AUTOSAR XML (schema 00050)
package /FCASWCs
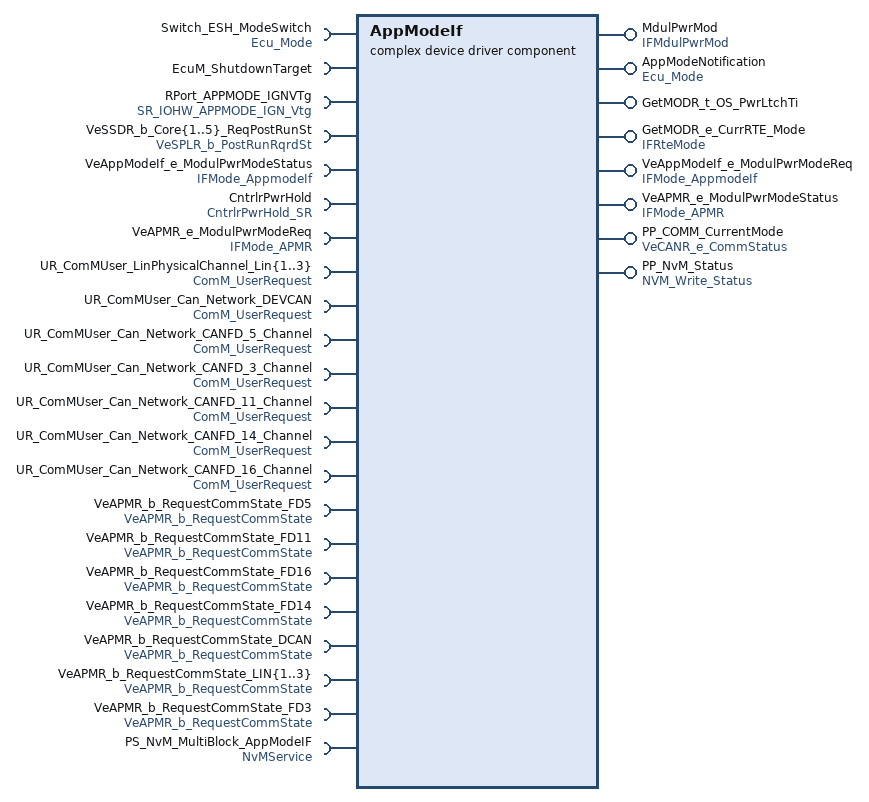
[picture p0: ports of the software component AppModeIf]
  complex device driver sw component type AppModeIf  # App Interface
    provide port MdulPwrMod: provided-interface=IFMdulPwrMod
    require port Switch_ESH_ModeSwitch: required-interface=Ecu_Mode
    provide port AppModeNotification: provided-interface=Ecu_Mode
    require port EcuM_ShutdownTarget: required-interface=EcuM_ShutdownTarget
    provide port GetMODR_t_OS_PwrLtchTi: provided-interface=GetMODR_t_OS_PwrLtchTi
    provide port GetMODR_e_CurrRTE_Mode: provided-interface=IFRteMode
      provided-com-specs:
        operation=GetMODR_e_CurrRTE_Mode, queue-length=1
        operation=GetMODR_b_InStrtUpMode, queue-length=1
        operation=GetMODR_b_InRunMode, queue-length=1
        operation=GetMODR_b_InPostRunMode, queue-length=1
        operation=GetMODR_b_InShtDwnMode, queue-length=1
        operation=GetMODR_b_InWakeUpMode, queue-length=1
    6 x require port:
      RPort_APPMODE_IGNVTg: required-interface=SR_IOHW_APPMODE_IGN_Vtg
      VeSSDR_b_Core{1..5}_ReqPostRunSt: required-interface=VeSPLR_b_PostRunRqrdSt
    provide port VeAppModeIf_e_ModulPwrModeReq: provided-interface=IFMode_AppmodeIf
    require port VeAppModeIf_e_ModulPwrModeStatus: required-interface=IFMode_AppmodeIf
    require port CntrlrPwrHold: required-interface=CntrlrPwrHold_SR
    provide port VeAPMR_e_ModulPwrModeStatus: provided-interface=IFMode_APMR
    4 x require port:
      VeAPMR_e_ModulPwrModeReq: required-interface=IFMode_APMR
      UR_ComMUser_LinPhysicalChannel_Lin{1..3}: required-interface=ComM_UserRequest
    provide port PP_COMM_CurrentMode: provided-interface=VeCANR_e_CommStatus
    16 x require port:
      UR_ComMUser_Can_Network_DEVCAN: required-interface=ComM_UserRequest
      UR_ComMUser_Can_Network_CANFD_5_Channel: required-interface=ComM_UserRequest
      UR_ComMUser_Can_Network_CANFD_3_Channel: required-interface=ComM_UserRequest
      UR_ComMUser_Can_Network_CANFD_11_Channel: required-interface=ComM_UserRequest
      UR_ComMUser_Can_Network_CANFD_14_Channel: required-interface=ComM_UserRequest
      UR_ComMUser_Can_Network_CANFD_16_Channel: required-interface=ComM_UserRequest
      VeAPMR_b_RequestCommState_FD5: required-interface=VeAPMR_b_RequestCommState
      VeAPMR_b_RequestCommState_FD11: required-interface=VeAPMR_b_RequestCommState
      VeAPMR_b_RequestCommState_FD16: required-interface=VeAPMR_b_RequestCommState
      VeAPMR_b_RequestCommState_FD14: required-interface=VeAPMR_b_RequestCommState
      VeAPMR_b_RequestCommState_DCAN: required-interface=VeAPMR_b_RequestCommState
      VeAPMR_b_RequestCommState_LIN{1..3}: required-interface=VeAPMR_b_RequestCommState
      VeAPMR_b_RequestCommState_FD3: required-interface=VeAPMR_b_RequestCommState
      PS_NvM_MultiBlock_AppModeIF: required-interface=NvMService
    provide port PP_NvM_Status: provided-interface=NVM_Write_Status
    behavior IBAppModeIf: data-type-mapping=[BswMMappingSet, MG_Shutdown_Mapping, SR_IO_HW_APPMODEIF_MappingSet, ADTtoIDTMapping], handle-termination-and-restart=NO-SUPPORT
      init event InitEvent: start-on-event=InitMode
      5 x operation invoked event:
        IsInPostRunMode: start-on-event=GetMODR_b_InPostRunMode, operation=GetMODR_e_CurrRTE_Mode.GetMODR_b_InPostRunMode
        IsInRunMode: start-on-event=GetMODR_b_InRunMode, operation=GetMODR_e_CurrRTE_Mode.GetMODR_b_InRunMode
        IsInShutDownMode: start-on-event=GetMODR_b_InShtDwnMode, operation=GetMODR_e_CurrRTE_Mode.GetMODR_b_InShtDwnMode
        IsInStartUpMode: start-on-event=GetMODR_b_InStrtUpMode, operation=GetMODR_e_CurrRTE_Mode.GetMODR_b_InStrtUpMode
        IsInWakeUpMode: start-on-event=GetMODR_b_InWakeUpMode, operation=GetMODR_e_CurrRTE_Mode.GetMODR_b_InWakeUpMode
      5 x timing event, all with period=0.01:
        TimingEvent: start-on-event=AppModeMgr
        TE_Mode: start-on-event=RE_Mode
        TE_APMR_Mode: start-on-event=RE_APMR_Mode
        TE_Comm_Status: start-on-event=RE_Comm_Status
        TE_NvMJobEndNotification: start-on-event=RE_NvMJobEndNotification
      port-api-options:
        enable-take-address=false, indirect-api=false, port=GetMODR_e_CurrRTE_Mode
        enable-take-address=false, indirect-api=false, port=MdulPwrMod
        enable-take-address=false, indirect-api=false, port=Switch_ESH_ModeSwitch
      15 x runnable:
        AppModeMgr: symbol=AppModeIf_AppModeMgr
          data-receive-point-by-values:
            6 x access:
              DRPV_IOHW_APPMODE_IGNVtg_VDP_0: accessed-variable=RPort_APPMODE_IGNVTg.IOHW_APPMODE_IGNVtg_VDP
              DRPV_VeSPLR_b_PostRunRqrdSt_0: accessed-variable=VeSSDR_b_Core1_ReqPostRunSt.VeSPLR_b_PostRunRqrdSt
              DRPV_VeSPLR_b_PostRunRqrdSt_1: accessed-variable=VeSSDR_b_Core2_ReqPostRunSt.VeSPLR_b_PostRunRqrdSt
              DRPV_VeSPLR_b_PostRunRqrdSt_2: accessed-variable=VeSSDR_b_Core3_ReqPostRunSt.VeSPLR_b_PostRunRqrdSt
              DRPV_VeSPLR_b_PostRunRqrdSt_3: accessed-variable=VeSSDR_b_Core4_ReqPostRunSt.VeSPLR_b_PostRunRqrdSt
              DRPV_VeSPLR_b_PostRunRqrdSt_4: accessed-variable=VeSSDR_b_Core5_ReqPostRunSt.VeSPLR_b_PostRunRqrdSt
          mode-access-point mode-group=MdulPwrMod.AppMode_MDGP_ESH_Mode:
            ident MAP_AppModeSwitch_ModeGroup
          mode-access-point mode-group=AppModeNotification.BswMEcuModeDclGroups:
            ident MAP_AppModeNotification_BswMEcuModeDclGroups
          mode-access-point mode-group=Switch_ESH_ModeSwitch.BswMEcuModeDclGroups:
            ident MAP_Switch_ESH_ModeSwitch_BswMEcuModeDclGroups
          mode switch point MSP_AppModeSwitch_ModeGroup: mode-group=MdulPwrMod.AppMode_MDGP_ESH_Mode
          mode switch point MSP_AppModeNotification_BswMEcuModeDclGroups: mode-group=AppModeNotification.BswMEcuModeDclGroups
          parameter access SCPVA_KeMODR_t_OS_PwrDwnMaxTi
          parameter access SCPVA_KeMODR_t_OS_PwrDwnTrigTi
          5 x sync call, all with timeout=0.0:
            SSCP_EcuM_ShutdownTarget_GetLastShutdownTarget: operation=EcuM_ShutdownTarget.GetLastShutdownTarget
            SSCP_EcuM_ShutdownTarget_GetShutdownCause: operation=EcuM_ShutdownTarget.GetShutdownCause
            SSCP_EcuM_ShutdownTarget_GetShutdownTarget: operation=EcuM_ShutdownTarget.GetShutdownTarget
            SSCP_EcuM_ShutdownTarget_SelectShutdownCause: operation=EcuM_ShutdownTarget.SelectShutdownCause
            SSCP_EcuM_ShutdownTarget_SelectShutdownTarget: operation=EcuM_ShutdownTarget.SelectShutdownTarget
        InitMode: symbol=AppModeIf_InitMode
          mode-access-point mode-group=MdulPwrMod.AppMode_MDGP_ESH_Mode:
            ident MAP_MdulPwrMod_AppMode_MDGP_ESH_Mode
          mode switch point MSP_MdulPwrMod_AppMode_MDGP_ESH_Mode: mode-group=MdulPwrMod.AppMode_MDGP_ESH_Mode
        GetMODR_b_InPostRunMode: can-be-invoked-concurrently=true, symbol=AppModeIf_GetMODR_b_InPostRunMode
        GetMODR_b_InRunMode: can-be-invoked-concurrently=true, symbol=AppModeIf_GetMODR_b_InRunMode
        GetMODR_b_InShtDwnMode: can-be-invoked-concurrently=true, symbol=AppModeIf_GetMODR_b_InShtDwnMode
        GetMODR_b_InStrtUpMode: can-be-invoked-concurrently=true, symbol=AppModeIf_GetMODR_b_InStrtUpMode
        GetMODR_b_InWakeUpMode: can-be-invoked-concurrently=true, symbol=AppModeIf_GetMODR_b_InWakeUpMode
        DcmExecute: symbol=AppModeIf_DcmExecute
        DcmKeyOnOffReset: symbol=AppModeIf_DcmKeyOnOffReset
        DcmHardReset: symbol=AppModeIf_DcmHardReset
        GetMODR_t_PostRunTmr: can-be-invoked-concurrently=true, symbol=AppModeIf_GetMODR_t_PostRunTmr
        RE_Mode: minimum-start-interval=0.01
          data-receive-point-by-values:
            access DRPV_Mode_AppModeIf: accessed-variable=VeAppModeIf_e_ModulPwrModeStatus.Mode
          data-send-points:
            access DSP_Mode_AppModeIf: accessed-variable=VeAppModeIf_e_ModulPwrModeReq.Mode
        RE_APMR_Mode: minimum-start-interval=0.01
          data-receive-point-by-values:
            access DRPV_Mode_APMR: accessed-variable=VeAPMR_e_ModulPwrModeReq.Mode
          data-send-points:
            access DSP_Mode_APMR: accessed-variable=VeAPMR_e_ModulPwrModeStatus.Mode
        RE_Comm_Status
          data-receive-point-by-values:
            9 x access:
              DRPV_VeAPMR_b_RequestCommState_FD3_0: accessed-variable=VeAPMR_b_RequestCommState_FD3.VeAPMR_b_RequestCommState_FD3
              DRPV_VeAPMR_b_RequestCommState_FD5_0: accessed-variable=VeAPMR_b_RequestCommState_FD5.VeAPMR_b_RequestCommState_FD5
              DRPV_VeAPMR_b_RequestCommState_FD11_0: accessed-variable=VeAPMR_b_RequestCommState_FD11.VeAPMR_b_RequestCommState_FD11
              DRPV_VeAPMR_b_RequestCommState_FD14_0: accessed-variable=VeAPMR_b_RequestCommState_FD14.VeAPMR_b_RequestCommState_FD14
              DRPV_VeAPMR_b_RequestCommState_FD16_0: accessed-variable=VeAPMR_b_RequestCommState_FD16.VeAPMR_b_RequestCommState_FD16
              DRPV_VeAPMR_b_RequestCommState_LIN{1..3}_0: accessed-variable=VeAPMR_b_RequestCommState_LIN{1..3}.VeAPMR_b_RequestCommState_LIN{1..3}
              DRPV_VeAPMR_b_RequestCommState_DCAN_0: accessed-variable=VeAPMR_b_RequestCommState_DCAN.VeAPMR_b_RequestCommState_DCAN
          data-send-points:
            9 x access:
              DSP_VeCANR_e_CommStatus_FD3_0: accessed-variable=PP_COMM_CurrentMode.VeCANR_e_CommStatus_FD3
              DSP_VeCANR_e_CommStatus_FD5_0: accessed-variable=PP_COMM_CurrentMode.VeCANR_e_CommStatus_FD5
              DSP_VeCANR_e_CommStatus_FD11_0: accessed-variable=PP_COMM_CurrentMode.VeCANR_e_CommStatus_FD11
              DSP_VeCANR_e_CommStatus_FD14_0: accessed-variable=PP_COMM_CurrentMode.VeCANR_e_CommStatus_FD14
              DSP_VeCANR_e_CommStatus_FD16_0: accessed-variable=PP_COMM_CurrentMode.VeCANR_e_CommStatus_FD16
              DSP_VeCANR_e_CommStatus_LIN{1..3}_0: accessed-variable=PP_COMM_CurrentMode.VeCANR_e_CommStatus_LIN{1..3}
              DSP_VeCANR_e_CommStatus_DCAN_0: accessed-variable=PP_COMM_CurrentMode.VeCANR_e_CommStatus_DCAN
          45 x sync call:
            SynchronousServerCallPoint_0: operation=UR_ComMUser_LinPhysicalChannel_Lin2.GetCurrentComMode
            SynchronousServerCallPoint_1: operation=UR_ComMUser_LinPhysicalChannel_Lin2.GetCurrentPNCComMode
            SynchronousServerCallPoint_2: operation=UR_ComMUser_LinPhysicalChannel_Lin2.GetMaxComMode
            SynchronousServerCallPoint_3: operation=UR_ComMUser_LinPhysicalChannel_Lin2.GetRequestedComMode
            SynchronousServerCallPoint_4: operation=UR_ComMUser_LinPhysicalChannel_Lin2.RequestComMode
            SynchronousServerCallPoint_5: operation=UR_ComMUser_Can_Network_CANFD_16_Channel.GetCurrentComMode
            SynchronousServerCallPoint_6: operation=UR_ComMUser_Can_Network_CANFD_16_Channel.GetCurrentPNCComMode
            SynchronousServerCallPoint_7: operation=UR_ComMUser_Can_Network_CANFD_16_Channel.GetMaxComMode
            SynchronousServerCallPoint_8: operation=UR_ComMUser_Can_Network_CANFD_16_Channel.GetRequestedComMode
            SynchronousServerCallPoint_9: operation=UR_ComMUser_Can_Network_CANFD_16_Channel.RequestComMode
            SynchronousServerCallPoint_10: operation=UR_ComMUser_Can_Network_CANFD_11_Channel.GetCurrentComMode
            SynchronousServerCallPoint_11: operation=UR_ComMUser_Can_Network_CANFD_11_Channel.GetCurrentPNCComMode
            SynchronousServerCallPoint_12: operation=UR_ComMUser_Can_Network_CANFD_11_Channel.GetMaxComMode
            SynchronousServerCallPoint_13: operation=UR_ComMUser_Can_Network_CANFD_11_Channel.GetRequestedComMode
            SynchronousServerCallPoint_14: operation=UR_ComMUser_Can_Network_CANFD_11_Channel.RequestComMode
            SynchronousServerCallPoint_15: operation=UR_ComMUser_Can_Network_CANFD_5_Channel.GetCurrentComMode
            SynchronousServerCallPoint_16: operation=UR_ComMUser_Can_Network_CANFD_5_Channel.GetCurrentPNCComMode
            SynchronousServerCallPoint_17: operation=UR_ComMUser_Can_Network_CANFD_5_Channel.GetMaxComMode
            SynchronousServerCallPoint_18: operation=UR_ComMUser_Can_Network_CANFD_5_Channel.GetRequestedComMode
            SynchronousServerCallPoint_19: operation=UR_ComMUser_Can_Network_CANFD_5_Channel.RequestComMode
            SynchronousServerCallPoint_20: operation=UR_ComMUser_LinPhysicalChannel_Lin1.GetCurrentComMode
            SynchronousServerCallPoint_21: operation=UR_ComMUser_LinPhysicalChannel_Lin1.GetCurrentPNCComMode
            SynchronousServerCallPoint_22: operation=UR_ComMUser_LinPhysicalChannel_Lin1.GetMaxComMode
            SynchronousServerCallPoint_23: operation=UR_ComMUser_LinPhysicalChannel_Lin1.GetRequestedComMode
            SynchronousServerCallPoint_24: operation=UR_ComMUser_LinPhysicalChannel_Lin1.RequestComMode
            SynchronousServerCallPoint_25: operation=UR_ComMUser_Can_Network_CANFD_14_Channel.GetCurrentComMode
            SynchronousServerCallPoint_26: operation=UR_ComMUser_Can_Network_CANFD_14_Channel.GetCurrentPNCComMode
            SynchronousServerCallPoint_27: operation=UR_ComMUser_Can_Network_CANFD_14_Channel.GetMaxComMode
            SynchronousServerCallPoint_28: operation=UR_ComMUser_Can_Network_CANFD_14_Channel.GetRequestedComMode
            SynchronousServerCallPoint_29: operation=UR_ComMUser_Can_Network_CANFD_14_Channel.RequestComMode
            SynchronousServerCallPoint_30: operation=UR_ComMUser_LinPhysicalChannel_Lin3.GetCurrentComMode
            SynchronousServerCallPoint_31: operation=UR_ComMUser_LinPhysicalChannel_Lin3.GetCurrentPNCComMode
            SynchronousServerCallPoint_32: operation=UR_ComMUser_LinPhysicalChannel_Lin3.GetMaxComMode
            SynchronousServerCallPoint_33: operation=UR_ComMUser_LinPhysicalChannel_Lin3.GetRequestedComMode
            SynchronousServerCallPoint_34: operation=UR_ComMUser_LinPhysicalChannel_Lin3.RequestComMode
            SynchronousServerCallPoint_35: operation=UR_ComMUser_Can_Network_DEVCAN.GetCurrentComMode
            SynchronousServerCallPoint_36: operation=UR_ComMUser_Can_Network_DEVCAN.GetCurrentPNCComMode
            SynchronousServerCallPoint_37: operation=UR_ComMUser_Can_Network_DEVCAN.GetMaxComMode
            SynchronousServerCallPoint_38: operation=UR_ComMUser_Can_Network_DEVCAN.GetRequestedComMode
            SynchronousServerCallPoint_39: operation=UR_ComMUser_Can_Network_DEVCAN.RequestComMode
            SynchronousServerCallPoint_40: operation=UR_ComMUser_Can_Network_CANFD_3_Channel.GetCurrentComMode
            SynchronousServerCallPoint_41: operation=UR_ComMUser_Can_Network_CANFD_3_Channel.GetCurrentPNCComMode
            SynchronousServerCallPoint_42: operation=UR_ComMUser_Can_Network_CANFD_3_Channel.GetMaxComMode
            SynchronousServerCallPoint_43: operation=UR_ComMUser_Can_Network_CANFD_3_Channel.GetRequestedComMode
            SynchronousServerCallPoint_44: operation=UR_ComMUser_Can_Network_CANFD_3_Channel.RequestComMode
        RE_NvMJobEndNotification
          data-send-points:
            access DSP_NVM_Multiblock_WriteStatus_0: accessed-variable=PP_NvM_Status.NVM_Multiblock_WriteStatus
          sync call SynchronousServerCallPoint_0: operation=PS_NvM_MultiBlock_AppModeIF.GetErrorStatus
      shared-parameters:
        parameter data prototype KeMODR_t_OS_PwrDwnMaxTi: sw-calibration-access=READ-WRITE, type=uint8, init-value=KeMODR_t_OS_PwrDwnMaxTi:30
package /PortInterfaces
  sender receiver interface NVM_Write_Status
    data NVM_Multiblock_WriteStatus: type=NvM_RequestResultType
